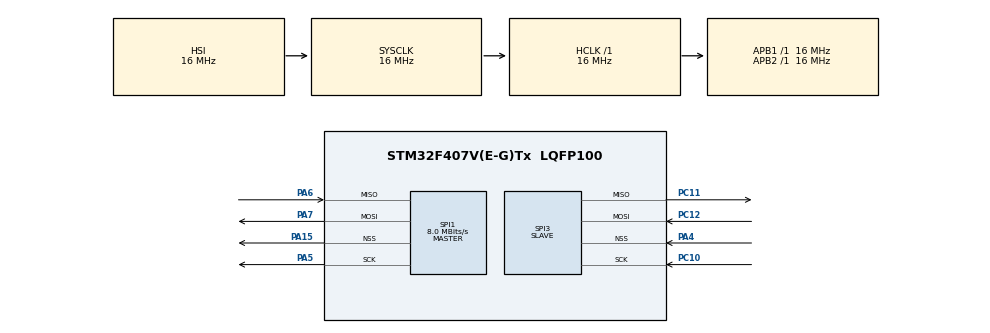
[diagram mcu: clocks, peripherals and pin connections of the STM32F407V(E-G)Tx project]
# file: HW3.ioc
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Dma.Request0=SPI1_TX
Dma.Request1=SPI3_RX
Dma.SPI1_TX.0.Direction=DMA_MEMORY_TO_PERIPH
Dma.SPI1_TX.0.FIFOMode=DMA_FIFOMODE_DISABLE
Dma.SPI1_TX.0.Instance=DMA2_Stream3
Dma.SPI1_TX.0.MemDataAlignment=DMA_MDATAALIGN_BYTE
Dma.SPI1_TX.0.MemInc=DMA_MINC_ENABLE
Dma.SPI1_TX.0.Mode=DMA_NORMAL
Dma.SPI1_TX.0.PeriphDataAlignment=DMA_PDATAALIGN_BYTE
Dma.SPI1_TX.0.PeriphInc=DMA_PINC_DISABLE
Dma.SPI1_TX.0.Priority=DMA_PRIORITY_HIGH
Dma.SPI3_RX.1.Direction=DMA_PERIPH_TO_MEMORY
Dma.SPI3_RX.1.FIFOMode=DMA_FIFOMODE_DISABLE
Dma.SPI3_RX.1.Instance=DMA1_Stream0
Dma.SPI3_RX.1.MemDataAlignment=DMA_MDATAALIGN_BYTE
Dma.SPI3_RX.1.MemInc=DMA_MINC_ENABLE
Dma.SPI3_RX.1.Mode=DMA_NORMAL
Dma.SPI3_RX.1.PeriphDataAlignment=DMA_PDATAALIGN_BYTE
Dma.SPI3_RX.1.PeriphInc=DMA_PINC_DISABLE
Dma.SPI3_RX.1.Priority=DMA_PRIORITY_HIGH
Mcu.Family=STM32F4
Mcu.Name=STM32F407V(E-G)Tx
Mcu.Package=LQFP100
NVIC.DMA1_Stream0_IRQn=true\:0\:0\:false\:false\:true\:false\:true\:true
NVIC.DMA2_Stream3_IRQn=true\:0\:0\:false\:false\:true\:false\:true\:true
NVIC.PriorityGroup=NVIC_PRIORITYGROUP_4
NVIC.SPI3_IRQn=true\:0\:0\:false\:false\:true\:true\:true\:true
PA13.Mode=Serial_Wire
PA13.Signal=SYS_JTMS-SWDIO
PA14.Mode=Serial_Wire
PA14.Signal=SYS_JTCK-SWCLK
PA15.Mode=NSS_Signal_Hard_Output
PA15.Signal=SPI1_NSS
PA4.Mode=NSS_Signal_Hard_Input
PA4.Signal=SPI3_NSS
PA5.Mode=Full_Duplex_Master
PA5.Signal=SPI1_SCK
PA6.Mode=Full_Duplex_Master
PA6.Signal=SPI1_MISO
PA7.Mode=Full_Duplex_Master
PA7.Signal=SPI1_MOSI
PC10.Mode=Full_Duplex_Slave
PC10.Signal=SPI3_SCK
PC11.Mode=Full_Duplex_Slave
PC11.Signal=SPI3_MISO
PC12.Mode=Full_Duplex_Slave
PC12.Signal=SPI3_MOSI
ProjectManager.HeapSize=0x200
ProjectManager.StackSize=0x400
ProjectManager.TargetToolchain=CMake
RCC.AHBFreq_Value=16000000
RCC.APB1Freq_Value=16000000
RCC.APB2Freq_Value=16000000
RCC.CortexFreq_Value=16000000
RCC.HSE_VALUE=25000000
RCC.HSI_VALUE=16000000
RCC.LSE_VALUE=32768
RCC.SYSCLKFreq_VALUE=16000000
RCC.VCOOutputFreq_Value=192000000
SPI1.CalculateBaudRate=8.0 MBits/s
SPI1.Direction=SPI_DIRECTION_2LINES
SPI1.Mode=SPI_MODE_MASTER
SPI1.VirtualNSS=VM_NSSHARD
SPI1.VirtualType=VM_MASTER
SPI3.Direction=SPI_DIRECTION_2LINES
SPI3.Mode=SPI_MODE_SLAVE
SPI3.VirtualNSS=VM_NSSHARD
SPI3.VirtualType=VM_SLAVE
board=custom

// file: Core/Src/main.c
/* USER CODE BEGIN Header */
/**
  ******************************************************************************
  * @file           : main.c
  * @brief          : Main program body
  ******************************************************************************
  * @attention
  *
  * Copyright (c) 2026 STMicroelectronics.
  * All rights reserved.
  *
  * This software is licensed under terms that can be found in the LICENSE file
  * in the root directory of this software component.
  * If no LICENSE file comes with this software, it is provided AS-IS.
  *
  ******************************************************************************
  */
/* USER CODE END Header */
#include "main.h"

SPI_HandleTypeDef hspi1;
SPI_HandleTypeDef hspi3;
DMA_HandleTypeDef hdma_spi1_tx;
DMA_HandleTypeDef hdma_spi3_rx;

/* USER CODE BEGIN PV */
  uint8_t receive_buff [2] = {0x00, 0x01};
  uint8_t transmit_buff[2] = {0xFB, 0xBB};
  volatile uint8_t rx_flaga = 0x00;
/* USER CODE END PV */

void SystemClock_Config(void);
static void MX_GPIO_Init(void);
static void MX_DMA_Init(void);
static void MX_SPI1_Init(void);
static void MX_SPI3_Init(void);

/* USER CODE BEGIN 0 */
void DMA_TEST(void) {
  while (HAL_SPI_GetState(&hspi3) != HAL_SPI_STATE_READY) {}

  HAL_SPI_Receive_DMA(&hspi3, receive_buff, 2);

  // Ждем, пока САМ КОНТРОЛЛЕР DMA поднимет флаг активности своего потока
  // Замените hdma_spi3_rx.Instance на ваш стрим (например, DMA1_Stream0)
  while (!(hdma_spi3_rx.Instance->CR & DMA_SxCR_EN)) {
    // Ждём аппаратного включения самого DMA
  }

  HAL_SPI_Transmit_DMA(&hspi1, transmit_buff, 2);
}
/* USER CODE END 0 */

int main(void)
{

  /* MCU Configuration--------------------------------------------------------*/

  /* Reset of all peripherals, Initializes the Flash interface and the Systick. */
  HAL_Init();

  /* Configure the system clock */
  SystemClock_Config();

  /* Initialize all configured peripherals */
  MX_GPIO_Init();
  MX_DMA_Init();
  MX_SPI1_Init();
  MX_SPI3_Init();
  /* USER CODE BEGIN 2 */
  DMA_TEST();
  // DMA_TEST();
  //DMA_TEST();
  /* USER CODE END 2 */

  /* Infinite loop */
  while (1)
  {

  }
}

void SystemClock_Config(void)
{
  RCC_OscInitTypeDef RCC_OscInitStruct = {0};
  RCC_ClkInitTypeDef RCC_ClkInitStruct = {0};

  /** Configure the main internal regulator output voltage
  */
  __HAL_RCC_PWR_CLK_ENABLE();
  __HAL_PWR_VOLTAGESCALING_CONFIG(PWR_REGULATOR_VOLTAGE_SCALE1);

  /** Initializes the RCC Oscillators according to the specified parameters
  * in the RCC_OscInitTypeDef structure.
  */
  RCC_OscInitStruct.OscillatorType = RCC_OSCILLATORTYPE_HSI;
  RCC_OscInitStruct.HSIState = RCC_HSI_ON;
  RCC_OscInitStruct.HSICalibrationValue = RCC_HSICALIBRATION_DEFAULT;
  RCC_OscInitStruct.PLL.PLLState = RCC_PLL_NONE;
  if (HAL_RCC_OscConfig(&RCC_OscInitStruct) != HAL_OK)
  {
    Error_Handler();
  }

  /** Initializes the CPU, AHB and APB buses clocks
  */
  RCC_ClkInitStruct.ClockType = RCC_CLOCKTYPE_HCLK|RCC_CLOCKTYPE_SYSCLK
                              |RCC_CLOCKTYPE_PCLK1|RCC_CLOCKTYPE_PCLK2;
  RCC_ClkInitStruct.SYSCLKSource = RCC_SYSCLKSOURCE_HSI;
  RCC_ClkInitStruct.AHBCLKDivider = RCC_SYSCLK_DIV1;
  RCC_ClkInitStruct.APB1CLKDivider = RCC_HCLK_DIV1;
  RCC_ClkInitStruct.APB2CLKDivider = RCC_HCLK_DIV1;

  if (HAL_RCC_ClockConfig(&RCC_ClkInitStruct, FLASH_LATENCY_0) != HAL_OK)
  {
    Error_Handler();
  }
}

static void MX_SPI1_Init(void)
{

  /* SPI1 parameter configuration*/
  hspi1.Instance = SPI1;
  hspi1.Init.Mode = SPI_MODE_MASTER;
  hspi1.Init.Direction = SPI_DIRECTION_2LINES;
  hspi1.Init.DataSize = SPI_DATASIZE_8BIT;
  hspi1.Init.CLKPolarity = SPI_POLARITY_LOW;
  hspi1.Init.CLKPhase = SPI_PHASE_1EDGE;
  hspi1.Init.NSS = SPI_NSS_HARD_OUTPUT;
  hspi1.Init.BaudRatePrescaler = SPI_BAUDRATEPRESCALER_2;
  hspi1.Init.FirstBit = SPI_FIRSTBIT_MSB;
  hspi1.Init.TIMode = SPI_TIMODE_DISABLE;
  hspi1.Init.CRCCalculation = SPI_CRCCALCULATION_DISABLE;
  hspi1.Init.CRCPolynomial = 10;
  if (HAL_SPI_Init(&hspi1) != HAL_OK)
  {
    Error_Handler();
  }

}

static void MX_SPI3_Init(void)
{

  /* SPI3 parameter configuration*/
  hspi3.Instance = SPI3;
  hspi3.Init.Mode = SPI_MODE_SLAVE;
  hspi3.Init.Direction = SPI_DIRECTION_2LINES;
  hspi3.Init.DataSize = SPI_DATASIZE_8BIT;
  hspi3.Init.CLKPolarity = SPI_POLARITY_LOW;
  hspi3.Init.CLKPhase = SPI_PHASE_1EDGE;
  hspi3.Init.NSS = SPI_NSS_HARD_INPUT;
  hspi3.Init.FirstBit = SPI_FIRSTBIT_MSB;
  hspi3.Init.TIMode = SPI_TIMODE_DISABLE;
  hspi3.Init.CRCCalculation = SPI_CRCCALCULATION_DISABLE;
  hspi3.Init.CRCPolynomial = 10;
  if (HAL_SPI_Init(&hspi3) != HAL_OK)
  {
    Error_Handler();
  }

}

static void MX_DMA_Init(void)
{

  /* DMA controller clock enable */
  __HAL_RCC_DMA2_CLK_ENABLE();
  __HAL_RCC_DMA1_CLK_ENABLE();

  /* DMA interrupt init */
  /* DMA1_Stream0_IRQn interrupt configuration */
  HAL_NVIC_SetPriority(DMA1_Stream0_IRQn, 0, 0);
  HAL_NVIC_EnableIRQ(DMA1_Stream0_IRQn);
  /* DMA2_Stream3_IRQn interrupt configuration */
  HAL_NVIC_SetPriority(DMA2_Stream3_IRQn, 0, 0);
  HAL_NVIC_EnableIRQ(DMA2_Stream3_IRQn);

}

static void MX_GPIO_Init(void)
{

  /* GPIO Ports Clock Enable */
  __HAL_RCC_GPIOA_CLK_ENABLE();
  __HAL_RCC_GPIOC_CLK_ENABLE();

}

/* USER CODE BEGIN 4 */
void HAL_SPI_RxCpltCallback(SPI_HandleTypeDef *hspi) {
  if (hspi->Instance == SPI3)  // Проверяем, что это наш SPI
  {
    rx_flaga = 0x01;  // Устанавливаем флаг
  }
}
/* USER CODE END 4 */

void Error_Handler(void)
{
  __disable_irq();
  while (1)
  {
  }
}
